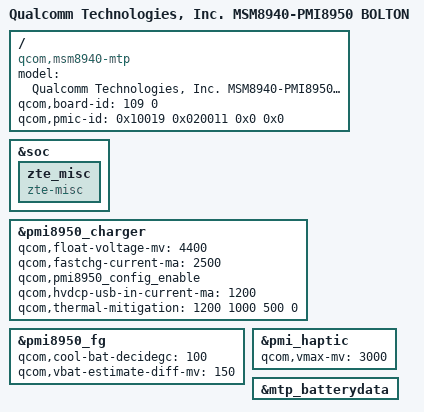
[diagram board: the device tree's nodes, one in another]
/*
 * Copyright (c) 2016, The Linux Foundation. All rights reserved.
 *
 * This program is free software; you can redistribute it and/or modify
 * it under the terms of the GNU General Public License version 2 and
 * only version 2 as published by the Free Software Foundation.
 *
 * This program is distributed in the hope that it will be useful,
 * but WITHOUT ANY WARRANTY; without even the implied warranty of
 * MERCHANTABILITY or FITNESS FOR A PARTICULAR PURPOSE.  See the
 * GNU General Public License for more details.
 */

/dts-v1/;

#include "msm8940.dtsi"
#include "msm8940-pmi8950-mtp.dtsi"
#include "zte-msm8940-bolton.dtsi"
#include "msm8940-camera-sensor-zte-bolton.dtsi"

#include "dsi-panel-truly-1080p-video.dtsi"
#include "dsi-panel-zte-tm-nt35695-tm-6p0-1080p-video.dtsi"
#include "dsi-panel-zte-lead_otm1906a_auo_6p0_1080p_cmd_n9560.dtsi"

/ {
	model = "Qualcomm Technologies, Inc. MSM8940-PMI8950 BOLTON";
	compatible = "qcom,msm8940-mtp", "qcom,msm8940", "qcom,mtp";
	qcom,board-id= <109 0>;
	qcom,pmic-id = <0x10019 0x020011 0x0 0x0>;
};

&soc {
	zte_misc {
		compatible = "zte-misc";
	};
};

&pmi8950_charger {
	qcom,float-voltage-mv = <4400>;
	qcom,fastchg-current-ma = <2500>;
	qcom,pmi8950_config_enable;
	qcom,hvdcp-usb-in-current-ma = <1200>;
	qcom,thermal-mitigation = <1200 1000 500 0>;
};
&pmi8950_fg{
	qcom,cool-bat-decidegc = <100>;
	qcom,vbat-estimate-diff-mv = <150>;
};
&pmi_haptic{
	qcom,vmax-mv = <3000>;
};

&mtp_batterydata {
		#include "zte_n9560_3990mah.dtsi"
		#include "zte_n9560_gy_3990mah.dtsi"
};
